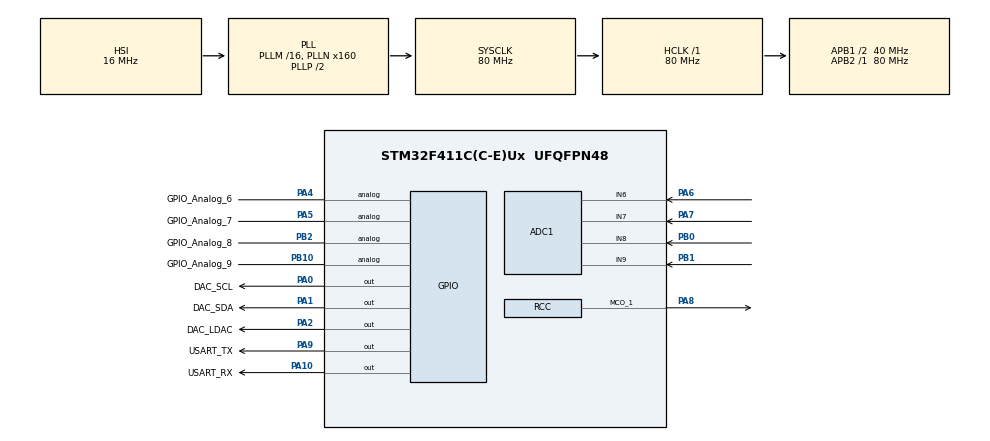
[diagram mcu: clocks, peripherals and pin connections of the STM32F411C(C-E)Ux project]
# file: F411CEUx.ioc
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ADC1.Channel-0\#ChannelRegularConversion=ADC_CHANNEL_6
ADC1.Channel-1\#ChannelRegularConversion=ADC_CHANNEL_7
ADC1.Channel-2\#ChannelRegularConversion=ADC_CHANNEL_8
ADC1.ClockPrescaler=ADC_CLOCK_SYNC_PCLK_DIV4
ADC1.ContinuousConvMode=ENABLE
ADC1.DMAContinuousRequests=ENABLE
ADC1.NbrOfConversion=3
ADC1.NbrOfConversionFlag=1
ADC1.Rank-0\#ChannelRegularConversion=1
ADC1.Rank-1\#ChannelRegularConversion=2
ADC1.Rank-2\#ChannelRegularConversion=3
ADC1.SamplingTime-0\#ChannelRegularConversion=ADC_SAMPLETIME_15CYCLES
ADC1.SamplingTime-1\#ChannelRegularConversion=ADC_SAMPLETIME_15CYCLES
ADC1.SamplingTime-2\#ChannelRegularConversion=ADC_SAMPLETIME_15CYCLES
ADC1.ScanConvMode=ENABLE
ADC1.master=1
Dma.ADC1.0.Direction=DMA_PERIPH_TO_MEMORY
Dma.ADC1.0.FIFOMode=DMA_FIFOMODE_DISABLE
Dma.ADC1.0.Instance=DMA2_Stream0
Dma.ADC1.0.MemDataAlignment=DMA_MDATAALIGN_HALFWORD
Dma.ADC1.0.MemInc=DMA_MINC_ENABLE
Dma.ADC1.0.Mode=DMA_CIRCULAR
Dma.ADC1.0.PeriphDataAlignment=DMA_PDATAALIGN_HALFWORD
Dma.ADC1.0.PeriphInc=DMA_PINC_DISABLE
Dma.ADC1.0.Priority=DMA_PRIORITY_HIGH
Dma.Request0=ADC1
Mcu.Family=STM32F4
Mcu.Name=STM32F411C(C-E)Ux
Mcu.Package=UFQFPN48
NVIC.DMA2_Stream0_IRQn=true\:0\:0\:false\:false\:true\:false
NVIC.PriorityGroup=NVIC_PRIORITYGROUP_4
PA0-WKUP.GPIO_Label=DAC_SCL
PA0-WKUP.GPIO_Speed=GPIO_SPEED_FREQ_LOW
PA0-WKUP.Signal=GPIO_Output
PA1.GPIO_Label=DAC_SDA
PA1.GPIO_Speed=GPIO_SPEED_FREQ_LOW
PA1.Signal=GPIO_Output
PA10.GPIO_Label=USART_RX
PA10.Signal=GPIO_Output
PA13.Mode=Serial_Wire
PA13.Signal=SYS_JTMS-SWDIO
PA14.Mode=Serial_Wire
PA14.Signal=SYS_JTCK-SWCLK
PA2.GPIO_Label=DAC_LDAC
PA2.Signal=GPIO_Output
PA4.GPIO_Label=GPIO_Analog_6
PA4.Signal=GPIO_Analog
PA5.GPIO_Label=GPIO_Analog_7
PA5.Signal=GPIO_Analog
PA6.Signal=ADCx_IN6
PA7.Signal=ADCx_IN7
PA8.Mode=Clock-out-1
PA8.Signal=RCC_MCO_1
PA9.GPIO_Label=USART_TX
PA9.Signal=GPIO_Output
PB0.Signal=ADCx_IN8
PB1.Signal=ADCx_IN9
PB10.GPIO_Label=GPIO_Analog_9
PB10.Signal=GPIO_Analog
PB2.GPIO_Label=GPIO_Analog_8
PB2.Signal=GPIO_Analog
ProjectManager.HeapSize=0x200
ProjectManager.StackSize=0x400
ProjectManager.TargetToolchain=MDK-ARM V5
RCC.48MHZClocksFreq_Value=40000000
RCC.AHBFreq_Value=80000000
RCC.APB1CLKDivider=RCC_HCLK_DIV2
RCC.APB1Freq_Value=40000000
RCC.APB1TimFreq_Value=80000000
RCC.APB2Freq_Value=80000000
RCC.APB2TimFreq_Value=80000000
RCC.CortexFreq_Value=80000000
RCC.HCLKFreq_Value=80000000
RCC.HSE_VALUE=25000000
RCC.HSI_VALUE=16000000
RCC.PLLN=160
RCC.RCC_MCO1Source=RCC_MCO1SOURCE_PLLCLK
RCC.SYSCLKFreq_VALUE=80000000
RCC.SYSCLKSource=RCC_SYSCLKSOURCE_PLLCLK
RCC.VCOOutputFreq_Value=160000000
SH.ADCx_IN6.0=ADC1_IN6,IN6
SH.ADCx_IN7.0=ADC1_IN7,IN7
SH.ADCx_IN8.0=ADC1_IN8,IN8
SH.ADCx_IN9.0=ADC1_IN9,IN9
board=custom

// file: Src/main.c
/* USER CODE BEGIN Header */
/**
  ******************************************************************************
  * @file           : main.c
  * @brief          : Main program body
  ******************************************************************************
  ** This notice applies to any and all portions of this file
  * that are not between comment pairs USER CODE BEGIN and
  * USER CODE END. Other portions of this file, whether
  * inserted by the user or by software development tools
  * are owned by their respective copyright owners.
  *
  * COPYRIGHT(c) 2020 STMicroelectronics
  *
  * Redistribution and use in source and binary forms, with or without modification,
  * are permitted provided that the following conditions are met:
  *   1. Redistributions of source code must retain the above copyright notice,
  *      this list of conditions and the following disclaimer.
  *   2. Redistributions in binary form must reproduce the above copyright notice,
  *      this list of conditions and the following disclaimer in the documentation
  *      and/or other materials provided with the distribution.
  *   3. Neither the name of STMicroelectronics nor the names of its contributors
  *      may be used to endorse or promote products derived from this software
  *      without specific prior written permission.
  *
  * THIS SOFTWARE IS PROVIDED BY THE COPYRIGHT HOLDERS AND CONTRIBUTORS "AS IS"
  * AND ANY EXPRESS OR IMPLIED WARRANTIES, INCLUDING, BUT NOT LIMITED TO, THE
  * IMPLIED WARRANTIES OF MERCHANTABILITY AND FITNESS FOR A PARTICULAR PURPOSE ARE
  * DISCLAIMED. IN NO EVENT SHALL THE COPYRIGHT HOLDER OR CONTRIBUTORS BE LIABLE
  * FOR ANY DIRECT, INDIRECT, INCIDENTAL, SPECIAL, EXEMPLARY, OR CONSEQUENTIAL
  * DAMAGES (INCLUDING, BUT NOT LIMITED TO, PROCUREMENT OF SUBSTITUTE GOODS OR
  * SERVICES; LOSS OF USE, DATA, OR PROFITS; OR BUSINESS INTERRUPTION) HOWEVER
  * CAUSED AND ON ANY THEORY OF LIABILITY, WHETHER IN CONTRACT, STRICT LIABILITY,
  * OR TORT (INCLUDING NEGLIGENCE OR OTHERWISE) ARISING IN ANY WAY OUT OF THE USE
  * OF THIS SOFTWARE, EVEN IF ADVISED OF THE POSSIBILITY OF SUCH DAMAGE.
  *
  ******************************************************************************
  */
/* USER CODE END Header */

#include "main.h"

/* USER CODE BEGIN Includes */
#include "hal_i2c.h"
/* USER CODE END Includes */

ADC_HandleTypeDef hadc1;
DMA_HandleTypeDef hdma_adc1;

void SystemClock_Config(void);
static void MX_GPIO_Init(void);
static void MX_DMA_Init(void);
static void MX_ADC1_Init(void);

/* USER CODE BEGIN 0 */
	uint16_t adcBuf[3];
/* USER CODE END 0 */

int main(void)
{

  /* MCU Configuration--------------------------------------------------------*/

  /* Reset of all peripherals, Initializes the Flash interface and the Systick. */
  HAL_Init();

  /* Configure the system clock */
  SystemClock_Config();

  /* Initialize all configured peripherals */
  MX_GPIO_Init();
  MX_DMA_Init();
  MX_ADC1_Init();
  /* USER CODE BEGIN 2 */
  HAL_I2C_Init();
  HAL_ADC_Start_DMA(&hadc1, (uint32_t *)adcBuf, sizeof(adcBuf));
  /* USER CODE END 2 */

  /* Infinite loop */
  while (1)
  {

  }
}

void SystemClock_Config(void)
{
  RCC_OscInitTypeDef RCC_OscInitStruct = {0};
  RCC_ClkInitTypeDef RCC_ClkInitStruct = {0};

  /**Configure the main internal regulator output voltage
  */
  __HAL_RCC_PWR_CLK_ENABLE();
  __HAL_PWR_VOLTAGESCALING_CONFIG(PWR_REGULATOR_VOLTAGE_SCALE1);
  /**Initializes the CPU, AHB and APB busses clocks
  */
  RCC_OscInitStruct.OscillatorType = RCC_OSCILLATORTYPE_HSI;
  RCC_OscInitStruct.HSIState = RCC_HSI_ON;
  RCC_OscInitStruct.HSICalibrationValue = RCC_HSICALIBRATION_DEFAULT;
  RCC_OscInitStruct.PLL.PLLState = RCC_PLL_ON;
  RCC_OscInitStruct.PLL.PLLSource = RCC_PLLSOURCE_HSI;
  RCC_OscInitStruct.PLL.PLLM = 16;
  RCC_OscInitStruct.PLL.PLLN = 160;
  RCC_OscInitStruct.PLL.PLLP = RCC_PLLP_DIV2;
  RCC_OscInitStruct.PLL.PLLQ = 4;
  if (HAL_RCC_OscConfig(&RCC_OscInitStruct) != HAL_OK)
  {
    Error_Handler();
  }
  /**Initializes the CPU, AHB and APB busses clocks
  */
  RCC_ClkInitStruct.ClockType = RCC_CLOCKTYPE_HCLK|RCC_CLOCKTYPE_SYSCLK
                              |RCC_CLOCKTYPE_PCLK1|RCC_CLOCKTYPE_PCLK2;
  RCC_ClkInitStruct.SYSCLKSource = RCC_SYSCLKSOURCE_PLLCLK;
  RCC_ClkInitStruct.AHBCLKDivider = RCC_SYSCLK_DIV1;
  RCC_ClkInitStruct.APB1CLKDivider = RCC_HCLK_DIV2;
  RCC_ClkInitStruct.APB2CLKDivider = RCC_HCLK_DIV1;

  if (HAL_RCC_ClockConfig(&RCC_ClkInitStruct, FLASH_LATENCY_2) != HAL_OK)
  {
    Error_Handler();
  }
  HAL_RCC_MCOConfig(RCC_MCO1, RCC_MCO1SOURCE_PLLCLK, RCC_MCODIV_1);
}

static void MX_ADC1_Init(void)
{

  ADC_ChannelConfTypeDef sConfig = {0};

  /**Configure the global features of the ADC (Clock, Resolution, Data Alignment and number of conversion)
  */
  hadc1.Instance = ADC1;
  hadc1.Init.ClockPrescaler = ADC_CLOCK_SYNC_PCLK_DIV4;
  hadc1.Init.Resolution = ADC_RESOLUTION_12B;
  hadc1.Init.ScanConvMode = ENABLE;
  hadc1.Init.ContinuousConvMode = ENABLE;
  hadc1.Init.DiscontinuousConvMode = DISABLE;
  hadc1.Init.ExternalTrigConvEdge = ADC_EXTERNALTRIGCONVEDGE_NONE;
  hadc1.Init.ExternalTrigConv = ADC_SOFTWARE_START;
  hadc1.Init.DataAlign = ADC_DATAALIGN_RIGHT;
  hadc1.Init.NbrOfConversion = 3;
  hadc1.Init.DMAContinuousRequests = ENABLE;
  hadc1.Init.EOCSelection = ADC_EOC_SINGLE_CONV;
  if (HAL_ADC_Init(&hadc1) != HAL_OK)
  {
    Error_Handler();
  }
  /**Configure for the selected ADC regular channel its corresponding rank in the sequencer and its sample time.
  */
  sConfig.Channel = ADC_CHANNEL_6;
  sConfig.Rank = 1;
  sConfig.SamplingTime = ADC_SAMPLETIME_15CYCLES;
  if (HAL_ADC_ConfigChannel(&hadc1, &sConfig) != HAL_OK)
  {
    Error_Handler();
  }
  /**Configure for the selected ADC regular channel its corresponding rank in the sequencer and its sample time.
  */
  sConfig.Channel = ADC_CHANNEL_7;
  sConfig.Rank = 2;
  if (HAL_ADC_ConfigChannel(&hadc1, &sConfig) != HAL_OK)
  {
    Error_Handler();
  }
  /**Configure for the selected ADC regular channel its corresponding rank in the sequencer and its sample time.
  */
  sConfig.Channel = ADC_CHANNEL_8;
  sConfig.Rank = 3;
  if (HAL_ADC_ConfigChannel(&hadc1, &sConfig) != HAL_OK)
  {
    Error_Handler();
  }

}

static void MX_DMA_Init(void)
{
  /* DMA controller clock enable */
  __HAL_RCC_DMA2_CLK_ENABLE();

  /* DMA interrupt init */
  /* DMA2_Stream0_IRQn interrupt configuration */
  HAL_NVIC_SetPriority(DMA2_Stream0_IRQn, 0, 0);
  HAL_NVIC_EnableIRQ(DMA2_Stream0_IRQn);

}

static void MX_GPIO_Init(void)
{
  GPIO_InitTypeDef GPIO_InitStruct = {0};

  /* GPIO Ports Clock Enable */
  __HAL_RCC_GPIOA_CLK_ENABLE();
  __HAL_RCC_GPIOB_CLK_ENABLE();

  /*Configure GPIO pin Output Level */
  HAL_GPIO_WritePin(GPIOA, DAC_SCL_Pin|DAC_SDA_Pin|DAC_LDAC_Pin|USART_TX_Pin
                          |USART_RX_Pin, GPIO_PIN_RESET);

  /*Configure GPIO pins : DAC_SCL_Pin DAC_SDA_Pin DAC_LDAC_Pin USART_TX_Pin
                           USART_RX_Pin */
  GPIO_InitStruct.Pin = DAC_SCL_Pin|DAC_SDA_Pin|DAC_LDAC_Pin|USART_TX_Pin
                          |USART_RX_Pin;
  GPIO_InitStruct.Mode = GPIO_MODE_OUTPUT_PP;
  GPIO_InitStruct.Pull = GPIO_NOPULL;
  GPIO_InitStruct.Speed = GPIO_SPEED_FREQ_LOW;
  HAL_GPIO_Init(GPIOA, &GPIO_InitStruct);

  /*Configure GPIO pins : GPIO_Analog_6_Pin GPIO_Analog_7_Pin */
  GPIO_InitStruct.Pin = GPIO_Analog_6_Pin|GPIO_Analog_7_Pin;
  GPIO_InitStruct.Mode = GPIO_MODE_ANALOG;
  GPIO_InitStruct.Pull = GPIO_NOPULL;
  HAL_GPIO_Init(GPIOA, &GPIO_InitStruct);

  /*Configure GPIO pins : GPIO_Analog_8_Pin GPIO_Analog_9_Pin */
  GPIO_InitStruct.Pin = GPIO_Analog_8_Pin|GPIO_Analog_9_Pin;
  GPIO_InitStruct.Mode = GPIO_MODE_ANALOG;
  GPIO_InitStruct.Pull = GPIO_NOPULL;
  HAL_GPIO_Init(GPIOB, &GPIO_InitStruct);

  /*Configure GPIO pin : PA8 */
  GPIO_InitStruct.Pin = GPIO_PIN_8;
  GPIO_InitStruct.Mode = GPIO_MODE_AF_PP;
  GPIO_InitStruct.Pull = GPIO_NOPULL;
  GPIO_InitStruct.Speed = GPIO_SPEED_FREQ_LOW;
  GPIO_InitStruct.Alternate = GPIO_AF0_MCO;
  HAL_GPIO_Init(GPIOA, &GPIO_InitStruct);

}

void Error_Handler(void)
{
}

/************************ (C) COPYRIGHT STMicroelectronics *****END OF FILE****/
